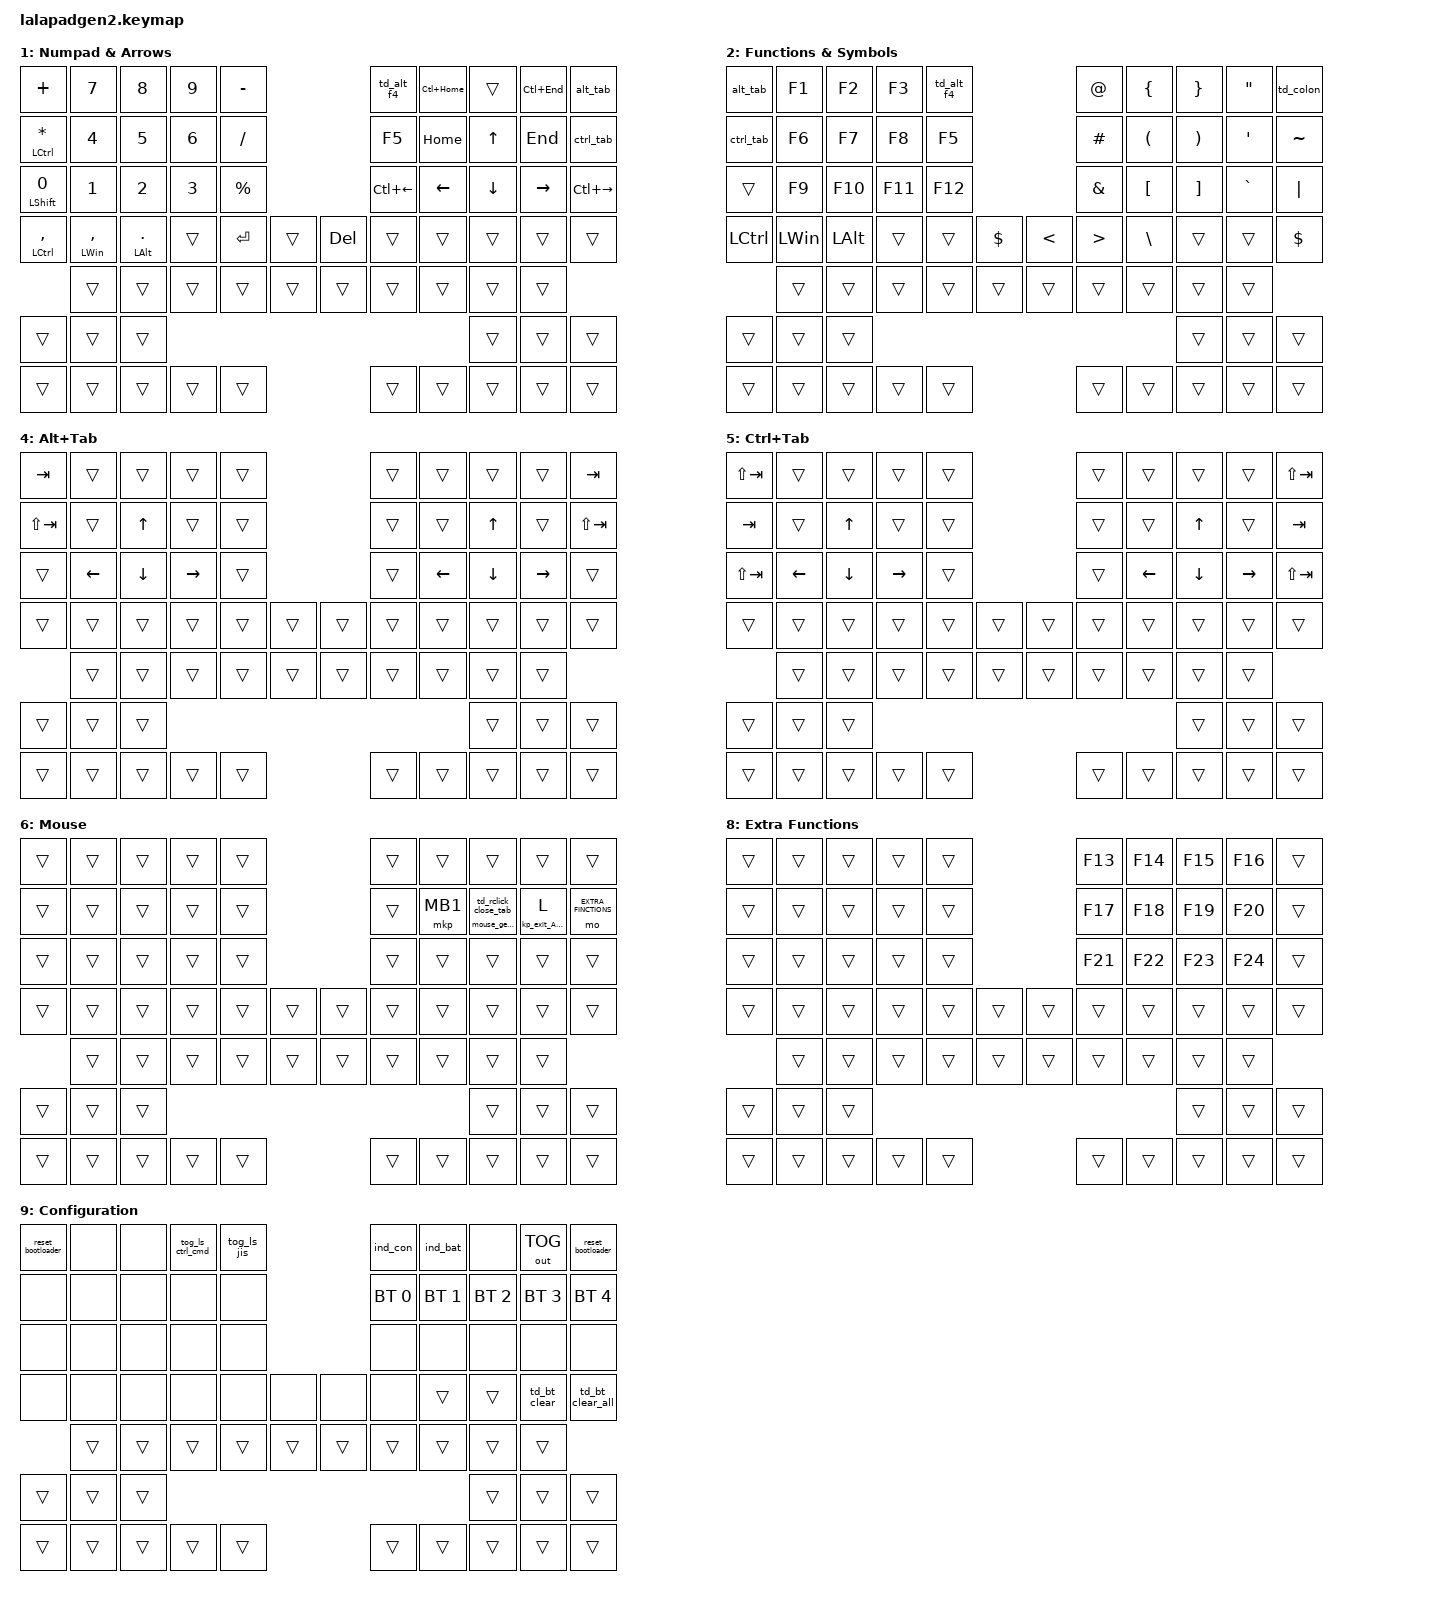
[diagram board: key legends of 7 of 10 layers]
#define ZMK_POINTING_DEFAULT_SCRL_VAL 1000

#include <input/processors.dtsi>
#include <dt-bindings/zmk/input_transform.h>
#include <zephyr/dt-bindings/input/input-event-codes.h>
#include <behaviors/rgbled_widget.dtsi>
#include <behaviors/quick_scroll.dtsi>
#include <input/processors/report_rate_limit.dtsi>


#include <behaviors.dtsi>
#include <dt-bindings/zmk/bt.h>
#include <dt-bindings/zmk/keys.h>
#include <dt-bindings/zmk/outputs.h>
#include <dt-bindings/zmk/pointing.h>

// #include <layout_shift.dtsi>
#include <layout_shift_kp_override.dtsi>

/ {
    behaviors {
        tog_ls_jis: tog_ls_jis {
            compatible = "zmk,behavior-layout-shift-toggle";
            #binding-cells = <0>;
            toggle-mode = "flip";
            label = "LAYOUT_SHIFT_TOGGLE_US_TO_JIS";
            display-name = "Toggle Layout Shift";
            layout-maps = <&layout_shift_map_us_to_jis>;
        };

        tog_ls_ctrl_cmd: tog_ls_ctrl_cmd {
            compatible = "zmk,behavior-layout-shift-toggle";
            #binding-cells = <0>;
            toggle-mode = "flip";
            label = "LAYOUT_SHIFT_TOGGLE_CTRL_CMD";
            display-name = "Toggle Layout Shift";
            layout-maps = <&layout_shift_map_swap_ctrl_cmd>;
        };
    };
};

&layout_shift_map_us_to_jis { priority = <0>; };
&layout_shift_map_swap_ctrl_cmd { priority = <1>; };

#include <mouse-gesture.dtsi>
#include <scroll-snap.dtsi>

#define DEFAULT 0
#define NUMPAD_AND_ARROWS 1
#define FUNCTIONS_AND_SYMBOLS 2
#define NAV 3
#define ALT_TAB 4
#define CTRL_TAB 5
#define MOUSE 6
#define MEDIA 7
#define EXTRA_FINCTIONS 8
#define CONFIGURATION 9

&qmsc {
    double-tap-ms = <350>;
};

&mt {
    tapping-term-ms = <200>;
    quick-tap-ms = <250>;
    flavor = "balanced";
};

&lt {
    tapping-term-ms = <200>;
    quick-tap-ms = <250>;
    flavor = "balanced";
};

&to { /delete-property/ locking; };

&tog { /delete-property/ locking; };

&sk { release-after-ms = <700>; };

&sl { release-after-ms = <1000>; };

&mouse_gesture_kp {
    tapping-term-ms = <200>;
    quick-tap-ms = <250>;
    flavor = "balanced";
};

&mouse_gesture_mkp {
    tapping-term-ms = <200>;
    quick-tap-ms = <250>;
    flavor = "balanced";
};

&zip_temp_layer {
    require-prior-idle-ms = <200>;
    excluded-positions = <
        16 17 18 19 // J K L ;
        20 29 30 // Z / Ctrl
        43 44 45 46 // Left directional switch
        47 48 49 50 // Right directional switch
    >;
};

&mkp_input_listener { input-processors = <&zip_temp_layer MOUSE 10000>; };

&zip_mouse_gesture {
    stroke-size = <150>;
    enable-eager-mode;
    suppress-movement;

    history_back {
        pattern = <GESTURE_RIGHT>;
        bindings = <&kp LA(LEFT)>;
    };

    history_forward {
        pattern = <GESTURE_LEFT>;
        bindings = <&kp LA(RIGHT)>;
    };

    close_tab {
        pattern = <GESTURE_DOWN GESTURE_RIGHT>;
        bindings = <&kp LC(W)>;
    };

    new_tab {
        pattern = <GESTURE_DOWN GESTURE_LEFT>;
        bindings = <&kp LC(T)>;
    };

    app_switcher {
        pattern = <GESTURE_DOWN GESTURE_UP>;
        bindings = <&kp LG(TAB)>;
    };

    virtual_desktop_prev {
        pattern = <GESTURE_LEFT GESTURE_DOWN>;
        bindings = <&kp LG(LC(LEFT))>;
    };

    virtual_desktop_next {
        pattern = <GESTURE_RIGHT GESTURE_DOWN>;
        bindings = <&kp LG(LC(RIGHT))>;
    };
};

&zip_scroll_snap {
    require-n-samples = <8>;
    immediate-snap-threshold = <750>;
    lock-duration-ms = <175>;
    lock-for-next-n-events = <8>;
    idle-reset-timeout-ms = <175>;
};

// &trackball_listener {
//     compatible = "zmk,input-listener";
//     input-processors = <
//         &zip_xy_transform (INPUT_TRANSFORM_XY_SWAP | INPUT_TRANSFORM_X_INVERT)
//         &zip_mouse_gesture
//         &zip_report_rate_limit 15
//         // &zip_cursor_snap
//     >;

//     auto-mouse-layer {
//         layers = <DEFAULT MOUSE>;
//         input-processors = <&zip_temp_layer MOUSE 10000>;
//         process-next;
//     };

//     scroller {
//         layers = <EXTRA_FINCTIONS MISC MEDIA>;
//         input-processors = <
//             &zip_xy_scaler 3 1
//             &zip_xy_transform (INPUT_TRANSFORM_XY_SWAP | INPUT_TRANSFORM_X_INVERT | INPUT_TRANSFORM_Y_INVERT)
//             &zip_xy_to_scroll_mapper
//             &zip_scroll_snap
//             &zip_report_rate_limit 15
//         >;

//         process-next;
//     };

//     disable-scroll-x {
//         layers = <EXTRA_FINCTIONS>;
//         input-processors = <&wheel_x_scaler 0 1>;

//         process-next;
//     };
// };

/ {
    input_processors {
        wheel_x_scaler: wheel_x_scaler {
            compatible = "zmk,input-processor-scaler";
            #input-processor-cells = <2>;
            type = <INPUT_EV_REL>;
            codes = <INPUT_REL_HWHEEL>;
            track-remainders;
        };
    };

    layer_listeners {
        compatible = "zmk,layer-listeners";

        // AML_indicator {
        //     layers = <MOUSE>;
        //     bindings = <&kp LS(LA(LC(LG(H)))) &kp LS(LA(LC(LG(H))))>;
        // };
        // AML {
        //     layers = <MOUSE>;
        //     bindings = <&to MOUSE &none>;
        // };
    };

    combos {
        compatible = "zmk,combos";

        eq {
            bindings = <&kp EQUAL>;
            key-positions = <0 1>;
            layers = <NUMPAD_AND_ARROWS>;
        };

        hat {
            bindings = <&kp CARET>;
            key-positions = <10 11>;
            layers = <NUMPAD_AND_ARROWS>;
        };

        middle_click {
            bindings = <&mkp MCLK>;
            key-positions = <18 19>;
            layers = <MOUSE>;
        };

        shift_middle_click {
            bindings = <&mkp_with_mod LEFT_SHIFT MCLK>;
            key-positions = <19 20>;
            layers = <MOUSE>;
        };

        Escape {
            bindings = <&kp ESCAPE>;
            key-positions = <0 1>;
            layers = <0>;
            require-prior-idle-ms = <300>;
        };

        caps_word {
            bindings = <&caps_word>;
            key-positions = <22 33>;
            layers = <0>;
            require-prior-idle-ms = <300>;
        };

        dot_slash_backslash {
            bindings = <&kp BACKSLASH>;
            key-positions = <33 32>;
            layers = <0>;
        };

        Ctrl_A {
            bindings = <&kp LC(A)>;
            key-positions = <10 11>;
            layers = <0>;
            require-prior-idle-ms = <300>;
        };

        Ctrl_Z {
            bindings = <&kp LC(Z)>;
            key-positions = <23 22>;
            layers = <0>;
            require-prior-idle-ms = <300>;
        };
    };

    macros {
        /omit-if-no-ref/

        exit_AML: exit_AML {
            compatible = "zmk,behavior-macro";
            wait-ms = <0>;
            tap-ms = <0>;
            #binding-cells = <0>;
            bindings = <&tog_off MOUSE>;
        };

        /omit-if-no-ref/

        kp_exit_AML: kp_exit_AML {
            compatible = "zmk,behavior-macro-one-param";
            wait-ms = <0>;
            tap-ms = <0>;
            #binding-cells = <1>;
            bindings = <&macro_param_1to1 &kp MACRO_PLACEHOLDER &exit_AML>;
        };

        /omit-if-no-ref/

        mod_exit_AML: mod_exit_AML {
            compatible = "zmk,behavior-macro-one-param";
            wait-ms = <0>;
            tap-ms = <0>;
            #binding-cells = <1>;
            bindings =
                <&macro_press>,
                <&macro_param_1to1 &kp MACRO_PLACEHOLDER>,
                <&macro_tap>,
                <&exit_AML>,
                <&macro_pause_for_release>,
                <&macro_release>,
                <&macro_param_1to1 &kp MACRO_PLACEHOLDER>;
        };

        /omit-if-no-ref/

        mkp_exit_AML: mkp_exit_AML {
            compatible = "zmk,behavior-macro-one-param";
            #binding-cells = <1>;
            bindings =
                <&macro_press>,
                <&macro_param_1to1 &mkp MACRO_PLACEHOLDER>,
                <&macro_pause_for_release>,
                <&macro_release>,
                <&macro_param_1to1 &mkp MACRO_PLACEHOLDER>,
                <&macro_tap>,
                <&sl MOUSE>;
        };

        /omit-if-no-ref/

        mo_exit_AML: mo_exit_AML {
            compatible = "zmk,behavior-macro-one-param";
            wait-ms = <0>;
            tap-ms = <0>;
            #binding-cells = <1>;
            bindings =
                <&macro_press>,
                <&macro_param_1to1 &mo MACRO_PLACEHOLDER>,
                <&macro_tap>,
                <&exit_AML>,
                <&macro_pause_for_release>,
                <&macro_release>,
                <&macro_param_1to1 &mo MACRO_PLACEHOLDER>,
                <&macro_tap>;
        };

        /omit-if-no-ref/

        ime_switch: ime_switch {
            compatible = "zmk,behavior-adaptive-key";
            #binding-cells = <0>;
            bindings = <&kp LANGUAGE_2>;

            ime_on {
                trigger-keys = <LANGUAGE_1 LANGUAGE_2>;
                bindings = <&kp LANGUAGE_1>;
                max-prior-idle-ms = <250>;
            };
        };

        /omit-if-no-ref/

        alt_tab: alt_tab {
            compatible = "zmk,behavior-smart-toggle";
            #binding-cells = <0>;
            bindings = <&mokp ALT_TAB LALT>, <&kp TAB>;
            ignored-key-positions = <
                10 19 // Shift+Tab
                12 21 22 23 17 26 27 28 // arrows
                13 16 52 53 54 55 56 57 // mouse clicks
            >;
        };

        /omit-if-no-ref/

        ctrl_tab: ctrl_tab {
            compatible = "zmk,behavior-smart-toggle";
            #binding-cells = <0>;
            bindings = <&mokp CTRL_TAB LCTRL>, <&kp TAB>;
            ignored-key-positions = <
                0 9 20 29 // Shift+Tab
                12 21 22 23 17 26 27 28 // arrows
                13 16 52 53 54 55 56 57 // mouse clicks
            >;
        };

        /omit-if-no-ref/

        mokp: mokp {
            compatible = "zmk,behavior-macro-two-param";
            wait-ms = <0>;
            tap-ms = <0>;
            #binding-cells = <2>;
            bindings =
                <&macro_press>,
                <&macro_param_1to1 &mo MACRO_PLACEHOLDER>,
                <&macro_param_2to1 &kp MACRO_PLACEHOLDER>,
                <&macro_pause_for_release>,
                <&macro_release>,
                <&macro_param_1to1 &mo MACRO_PLACEHOLDER>,
                <&macro_param_2to1 &kp MACRO_PLACEHOLDER>;
        };

        /omit-if-no-ref/

        kp_to: kp_to {
            compatible = "zmk,behavior-macro-two-param";
            wait-ms = <0>;
            tap-ms = <0>;
            #binding-cells = <2>;
            bindings = <&macro_param_1to1 &kp MACRO_PLACEHOLDER &macro_param_2to1 &to MACRO_PLACEHOLDER>;
        };

        /omit-if-no-ref/

        to_kp: to_kp {
            compatible = "zmk,behavior-macro-two-param";
            #binding-cells = <2>;
            bindings = <&macro_param_1to1 &to MACRO_PLACEHOLDER &macro_param_2to1 &kp MACRO_PLACEHOLDER>;
        };

        /omit-if-no-ref/

        zoom_in: zoom_in {
            compatible = "zmk,behavior-macro";
            #binding-cells = <0>;
            bindings = <&kt_on LCTRL &msc SCRL_UP &kt_off LCTRL>;
        };

        /omit-if-no-ref/

        zoom_out: zoom_out {
            compatible = "zmk,behavior-macro";
            #binding-cells = <0>;
            bindings = <&kt_on LCTRL &msc SCRL_DOWN &kt_off LCTRL>;
        };

    };

    behaviors {
        /omit-if-no-ref/

        tog_on: toggle_layer_on {
            compatible = "zmk,behavior-toggle-layer";
            #binding-cells = <1>;
            display-name = "Toggle Layer On";
            toggle-mode = "on";
        };

        /omit-if-no-ref/

        tog_off: toggle_layer_off {
            compatible = "zmk,behavior-toggle-layer";
            #binding-cells = <1>;
            display-name = "Toggle Layer Off";
            toggle-mode = "off";
        };

        /omit-if-no-ref/

        kt_on: key_toggle_on_only {
            compatible = "zmk,behavior-key-toggle";
            #binding-cells = <1>;
            display-name = "Key Toggle On";
            toggle-mode = "on";
        };

        /omit-if-no-ref/

        kt_off: key_toggle_off_only {
            compatible = "zmk,behavior-key-toggle";
            #binding-cells = <1>;
            display-name = "Key Toggle Off";
            toggle-mode = "off";
        };

        /omit-if-no-ref/

        td_colon: td_colon {
            compatible = "zmk,behavior-tap-dance";
            #binding-cells = <0>;
            bindings = <&kp COLON>, <&kp SEMICOLON>;

            tapping-term-ms = <250>;
        };

        /omit-if-no-ref/

        td_q_escape: td_q_escape {
            compatible = "zmk,behavior-tap-dance";
            #binding-cells = <0>;
            tapping-term-ms = <250>;
            bindings = <&kp Q>, <&kp ESCAPE>;
        };

        /omit-if-no-ref/

        td_ZenkakuHankaku: td_ZenkakuHankaku {
            compatible = "zmk,behavior-tap-dance";

            // compatible = "zmk,behavior-eager-tap-dance";

            #binding-cells = <0>;
            tapping-term-ms = <250>;
            bindings = <&kp LANGUAGE_2>, <&kp LANGUAGE_1>;
        };

        /omit-if-no-ref/

        td_ZenkakuHankaku_exit_AML: td_ZenkakuHankaku_exit_AML {
            wait-ms = <0>;
            tap-ms = <0>;
            compatible = "zmk,behavior-macro";
            #binding-cells = <0>;
            bindings = <&td_ZenkakuHankaku &exit_AML>;
        };

        /omit-if-no-ref/

        windows_sleep: windows_sleep {
            compatible = "zmk,behavior-macro";
            wait-ms = <200>;
            tap-ms = <100>;
            #binding-cells = <0>;
            bindings = <&kp LG(X) &kp U &kp S>;
        };

        /omit-if-no-ref/

        screensot_save: screensot_save {
            compatible = "zmk,behavior-macro";
            #binding-cells = <0>;
            bindings = <&kp LS(F11)>;
            label = "SCREENSOT_SAVE";
        };

        mkp_with_mod: mkp_with_mod {
            compatible = "zmk,behavior-macro-two-param";
            #binding-cells = <2>;
            bindings =
                <&macro_press>,
                <&macro_param_1to1 &kp MACRO_PLACEHOLDER &macro_param_2to1 &mkp MACRO_PLACEHOLDER>,
                <&macro_pause_for_release>,
                <&macro_release>,
                <&macro_param_2to1 &mkp MACRO_PLACEHOLDER &macro_param_1to1 &kp MACRO_PLACEHOLDER>;

            label = "MKP_WITH_MOD";
        };

        /omit-if-no-ref/

        screenshot_copy: screenshot_copy {
            compatible = "zmk,behavior-mod-morph";
            bindings = <&kp LA(PRINTSCREEN)>, <&kp LA(PRINTSCREEN)>;

            #binding-cells = <0>;
            mods = <(MOD_LSFT|MOD_LALT)>;
            keep-mods = <(MOD_LALT)>;
        };

        /omit-if-no-ref/

        mod_morph_exclamation: mod_morph_exclamation {
            compatible = "zmk,behavior-mod-morph";
            bindings = <&kp COMMA>, <&kp EXCL>;

            #binding-cells = <0>;
            mods = <(MOD_LSFT)>;
        };

        /omit-if-no-ref/

        mod_morph_question: mod_morph_question {
            compatible = "zmk,behavior-mod-morph";
            bindings = <&kp PERIOD>, <&kp QUESTION>;

            #binding-cells = <0>;
            mods = <(MOD_LSFT)>;
        };

        /omit-if-no-ref/

        mod_morph_slash: mod_morph_slash {
            compatible = "zmk,behavior-mod-morph";
            bindings = <&kp SLASH>, <&kp BACKSLASH>;

            #binding-cells = <0>;
            mods = <(MOD_LSFT)>;
        };

        /omit-if-no-ref/

        td_alt_f4: td_alt_f4 {
            compatible = "zmk,behavior-tap-dance";
            #binding-cells = <0>;
            bindings = <&kp F4>, <&kp LA(F4)>;

            tapping-term-ms = <250>;
        };

        /omit-if-no-ref/

        lt_exit_AML: lt_exit_AML {
            compatible = "zmk,behavior-hold-tap";
            bindings = <&mo_exit_AML>, <&kp_exit_AML>;

            #binding-cells = <2>;
            tapping-term-ms = <200>;
            quick-tap-ms = <200>;
            flavor = "balanced";
        };

        /omit-if-no-ref/

        lt_exit_AML_on_hold: lt_exit_AML_on_hold {
            compatible = "zmk,behavior-hold-tap";
            bindings = <&mo_exit_AML>, <&kp>;

            #binding-cells = <2>;
            tapping-term-ms = <200>;
            quick-tap-ms = <200>;
            flavor = "balanced";
        };

        /omit-if-no-ref/

        mt_exit_AML: mt_exit_AML {
            compatible = "zmk,behavior-hold-tap";
            bindings = <&mod_exit_AML>, <&kp_exit_AML>;

            #binding-cells = <2>;
            tapping-term-ms = <200>;
            flavor = "balanced";
            quick-tap-ms = <200>;
        };

        /omit-if-no-ref/

        mt_exit_AML_on_tap: mt_exit_AML_on_tap {
            compatible = "zmk,behavior-hold-tap";
            bindings = <&kp>, <&kp_exit_AML>;

            #binding-cells = <2>;
            tapping-term-ms = <200>;
            flavor = "balanced";
            quick-tap-ms = <200>;
        };

        /omit-if-no-ref/

        encoder_zoom: encoder_zoom {
            compatible = "zmk,behavior-sensor-rotate";
            #sensor-binding-cells = <0>;
            bindings = <&zoom_out>, <&zoom_in>;
        };

        /omit-if-no-ref/

        encoder_volume: encoder_volume {
            compatible = "zmk,behavior-sensor-rotate";
            #sensor-binding-cells = <0>;
            bindings = <&kp C_VOLUME_DOWN>, <&kp C_VOLUME_UP>;
        };

        // /omit-if-no-ref/

        lt_zoom_out: lt_zoom_out {
            compatible = "zmk,behavior-hold-tap";
            bindings = <&mo>, <&zoom_out>;

            #binding-cells = <2>;
            tapping-term-ms = <200>;
            quick-tap-ms = <200>;
            flavor = "balanced";
        };

        /omit-if-no-ref/

        td_bt_clear: td_bt_clear {
            compatible = "zmk,behavior-tap-dance";
            #binding-cells = <0>;
            bindings = <&none>, <&none>, <&bt BT_CLR>;

            tapping-term-ms = <250>;
        };

        /omit-if-no-ref/

        td_bt_clear_all: td_bt_clear_all {
            compatible = "zmk,behavior-tap-dance";
            #binding-cells = <0>;
            tapping-term-ms = <250>;
            bindings = <&none>, <&none>, <&bt BT_CLR_ALL>;
        };

        /omit-if-no-ref/

        td_copy_paste: td_copy_paste {
            compatible = "zmk,behavior-tap-dance";
            #binding-cells = <0>;
            bindings = <&kp_exit_AML LC(C)>, <&kp_exit_AML LC(V)>;

            tapping-term-ms = <250>;
        };

        /omit-if-no-ref/

        hold_bootloader: hold_bootloader {
            compatible = "zmk,behavior-hold-tap";
            #binding-cells = <2>;
            bindings = <&bootloader>, <&none>;
            tapping-term-ms = <250>;
            flavor = "tap-preferred";
        };

        /omit-if-no-ref/

        reset_bootloader: reset_bootloader {
            compatible = "zmk,behavior-tap-dance";
            #binding-cells = <0>;
            bindings = <&hold_bootloader 0 0>, <&sys_reset>;
            tapping-term-ms = <300>;
        };

        /omit-if-no-ref/

        td_rclick_close_tab: td_rclick_close_tab {
            compatible = "zmk,behavior-tap-dance";
            #binding-cells = <0>;
            bindings = <&mkp RCLK>, <&kp LC(W)>;

            tapping-term-ms = <250>;
        };

        /omit-if-no-ref/

        td_rclick_close_tab_mouse_gesture: td_rclick_close_tab_mouse_gesture {
            compatible = "zmk,behavior-hold-tap";
            #binding-cells = <2>;
            bindings = <&mouse_gesture>, <&td_rclick_close_tab>;

            tapping-term-ms = <150>;
            flavor = "balanced";
        };
    };

    keymap {
        compatible = "zmk,keymap";

        DEFAULT {
            display-name = "Default";
            bindings = <
&mt LWIN Q                        &mt LALT W        &kp E         &kp R         &kp T                                    &kp Y                    &kp U                    &kp I                   &kp O                &lt MEDIA P
&mt LCTRL A                       &kp S             &kp D         &kp F         &kp G                                    &kp H                    &kp J                    &mouse_gesture_kp 0 K   &kp L                &lt EXTRA_FINCTIONS MINUS
&mt_exit_AML_on_tap LEFT_SHIFT Z  &mt LEFT_SHIFT X  &kp C         &kp V                          &kp B                                                                        &kp N                    &kp M                    &mod_morph_exclamation  &mod_morph_question  &mt LEFT_SHIFT SLASH
&kp LCTRL                         &kp LEFT_WIN      &kp LEFT_ALT  &ime_switch   &lt FUNCTIONS_AND_SYMBOLS SPACE  &lt NAV TAB  &lt NAV BACKSPACE  &lt NUMPAD_AND_ARROWS ENTER  &lt NUMPAD_AND_ARROWS ENTER  &mo CONFIGURATION  &none  &lt EXTRA_FINCTIONS ESCAPE
                                  &none  &kp LG(LC(RIGHT))  &qmsc MOVE_Y(-120)  &kp LG(LC(LEFT))  &qmsc MOVE_Y(120)  &qmsc MOVE_Y(120)  &kp LA(LEFT)  &qmsc MOVE_Y(-120)  &kp LA(RIGHT)  &none
&mkp LCLK                         &mkp RCLK         &mkp MCLK                                                                                                                                                                   &mkp LCLK               &mkp RCLK            &mkp MCLK
&mkp MB4                          &mkp MB5          &kp LG(TAB)   &none                          &kp LCTRL                                                                    &kp LG(LC(LEFT))         &kp LG(LC(RIGHT))        &kp LG(TAB)             &none                &kp LCTRL
            >;
        };


        NUMPAD_AND_ARROWS {
            display-name = "Numpad & Arrows";
            bindings = <
&kp PLUS                   &kp N7              &kp N8               &kp N9  &kp MINUS                        &td_alt_f4    &kp LC(HOME)  &trans        &kp LC(END)  &alt_tab
&mt LEFT_CONTROL ASTERISK  &kp N4              &kp N5               &kp N6  &kp SLASH                        &kp F5        &kp HOME      &kp UP_ARROW  &kp END      &ctrl_tab
&mt LEFT_SHIFT N0          &kp N1              &kp N2               &kp N3  &kp PERCENT                      &kp LC(LEFT)  &kp LEFT      &kp DOWN      &kp RIGHT    &kp LC(RIGHT)
&mt LCTRL COMMA            &mt LEFT_WIN COMMA  &mt LEFT_ALT PERIOD  &trans  &kp ENTER    &trans  &kp DELETE  &trans        &trans        &trans        &trans       &trans
                           &trans              &trans               &trans  &trans       &trans  &trans      &trans        &trans        &trans        &trans
&trans                     &trans              &trans                                                                                    &trans        &trans       &trans
&trans                     &trans              &trans               &trans  &trans                           &trans        &trans        &trans        &trans       &trans
            >;
        };

        FUNCTIONS_AND_SYMBOLS {
            display-name = "Functions & Symbols";
            bindings = <
&alt_tab   &kp F1        &kp F2        &kp F3   &td_alt_f4                         &kp AT_SIGN       &kp LEFT_BRACE        &kp RIGHT_BRACE        &kp DOUBLE_QUOTES  &td_colon
&ctrl_tab  &kp F6        &kp F7        &kp F8   &kp F5                             &kp HASH          &kp LEFT_PARENTHESIS  &kp RIGHT_PARENTHESIS  &kp SINGLE_QUOTE   &kp TILDE
&trans        &kp F9        &kp F10       &kp F11  &kp F12                            &kp AMPERSAND     &kp LEFT_BRACKET      &kp RIGHT_BRACKET      &kp GRAVE          &kp PIPE
&kp LCTRL  &kp LEFT_WIN  &kp LEFT_ALT  &trans   &trans      &kp DOLLAR  &kp LESS_THAN  &kp GREATER_THAN  &kp BSLH  &trans  &trans  &kp DOLLAR
              &trans        &trans        &trans   &trans      &trans  &trans         &trans            &trans                &trans                 &trans
&trans        &trans        &trans                                                                                            &trans                 &trans             &trans
&trans        &trans        &trans        &trans   &trans                             &trans            &trans                &trans                 &trans             &trans
            >;
        };

        NAV {
            display-name = "Navigations";
            bindings = <
&alt_tab              &kp LC(LG(LEFT))        &kp LG(TAB)       &kp LG(LC(RIGHT))        &trans                                &trans      &kp LC(W)                 &kp LS(LC(T))             &kp LC(T)          &alt_tab
&ctrl_tab             &kp LG(LS(LEFT_ARROW))  &kp LG(UP_ARROW)  &kp LG(LS(RIGHT_ARROW))  &trans                                &trans      &kp_exit_AML LC(PAGE_UP)  &kp_exit_AML LA(UP_ARROW)  &kp LC(PAGE_DOWN)  &ctrl_tab
&kp LA(LC(LG(DOWN)))  &kp LG(LEFT_ARROW)      &kp LG(DOWN)      &kp LG(RIGHT_ARROW)      &screenshot_copy                      &kp C_MUTE  &kp LA(LEFT)              &kp LA(DOWN)               &kp LA(RIGHT)      &trans
&trans                &trans                  &trans            &trans                   &trans  &screensot_save  &kp C_VOLUME_UP  &kp DELETE  &kp_exit_AML C_VOLUME_DOWN  &trans  &trans  &trans
                      &trans                  &trans            &trans                   &trans            &trans  &trans      &trans      &trans                    &trans                 &trans
&trans                &trans                  &trans                                                                                                                 &trans                 &trans             &trans
&trans                &trans                  &trans            &trans                   &trans                                &trans      &trans                    &trans                 &trans             &trans
            >;
        };

        ALT_TAB {
            display-name = "Alt+Tab";
            bindings = <
&kp TAB      &trans    &trans    &trans     &trans                  &trans  &trans    &trans    &trans     &kp TAB
&kp LS(TAB)  &trans    &kp UP    &trans     &trans                  &trans  &trans    &kp UP    &trans     &kp LS(TAB)
&trans       &kp LEFT  &kp DOWN  &kp RIGHT  &trans                  &trans  &kp LEFT  &kp DOWN  &kp RIGHT  &trans
&trans       &trans    &trans    &trans     &trans  &trans  &trans  &trans  &trans    &trans    &trans     &trans
             &trans    &trans    &trans     &trans  &trans  &trans  &trans  &trans    &trans    &trans
&trans       &trans    &trans                                                         &trans    &trans     &trans
&trans       &trans    &trans    &trans     &trans                  &trans  &trans    &trans    &trans     &trans
            >;
        };

        CTRL_TAB {
            display-name = "Ctrl+Tab";
            bindings = <
&kp LS(TAB)  &trans    &trans    &trans     &trans                  &trans  &trans    &trans    &trans     &kp LS(TAB)
&kp TAB      &trans    &kp UP    &trans     &trans                  &trans  &trans    &kp UP    &trans     &kp TAB
&kp LS(TAB)  &kp LEFT  &kp DOWN  &kp RIGHT  &trans                  &trans  &kp LEFT  &kp DOWN  &kp RIGHT  &kp LS(TAB)
&trans       &trans    &trans    &trans     &trans  &trans  &trans  &trans  &trans    &trans    &trans     &trans
             &trans    &trans    &trans     &trans  &trans  &trans  &trans  &trans    &trans    &trans
&trans       &trans    &trans                                                         &trans    &trans     &trans
&trans       &trans    &trans    &trans     &trans                  &trans  &trans    &trans    &trans     &trans
            >;
        };

        MOUSE {
            display-name = "Mouse";
            bindings = <
&trans  &trans  &trans  &trans   &trans                  &trans  &trans    &trans                                  &trans  &trans
&trans  &trans  &trans  &trans  &trans                  &trans  &mkp MB1  &td_rclick_close_tab_mouse_gesture 0 0  &kp_exit_AML L  &mo EXTRA_FINCTIONS
&trans  &trans  &trans  &trans   &trans                  &trans  &trans    &trans                                  &trans  &trans
&trans  &trans  &trans  &trans   &trans  &trans  &trans  &trans  &trans    &trans                                  &trans  &trans
        &trans  &trans  &trans  &trans   &trans  &trans  &trans  &trans  &trans  &trans
&trans  &trans  &trans                                                     &trans                                  &trans  &trans
&trans  &trans  &trans  &trans   &trans                  &trans  &trans    &trans                                  &trans  &trans
            >;
        };

        MEDIA {
            display-name = "Media";
            bindings = <
&trans  &trans  &trans  &trans  &trans                  &kp C_PREV         &kp C_PLAY_PAUSE   &kp C_NEXT       &trans  &trans
&trans  &trans  &trans  &trans  &trans                  &kp C_VOLUME_DOWN  &kp C_MUTE         &kp C_VOLUME_UP  &trans  &trans
&trans  &trans  &trans  &trans  &trans                  &trans             &kp LS(LA(LC(M)))  &trans           &trans  &trans
&trans  &trans  &trans  &trans  &trans  &trans  &trans  &trans             &trans             &trans           &trans  &trans
        &trans  &trans  &trans  &trans  &trans  &trans  &trans             &trans             &trans           &trans
&trans  &trans  &trans                                                                        &trans           &trans  &trans
&trans  &trans  &trans  &trans  &trans                  &trans             &trans             &trans           &trans  &trans
            >;
        };

        EXTRA_FINCTIONS {
            display-name = "Extra Functions";
            bindings = <
&trans  &trans  &trans  &trans                         &trans                  &kp F13  &kp F14  &kp F15  &kp F16  &trans
&trans  &trans  &trans  &trans                         &trans                  &kp F17  &kp F18  &kp F19  &kp F20  &trans
&trans  &trans  &trans  &trans                         &trans                  &kp F21  &kp F22  &kp F23  &kp F24  &trans
&trans  &trans  &trans  &trans  &trans  &trans  &trans  &trans  &trans  &trans  &trans  &trans
        &trans  &trans  &trans                         &trans  &trans  &trans  &trans   &trans   &trans   &trans
&trans  &trans  &trans                                                                           &trans   &trans   &trans
&trans  &trans  &trans  &trans                         &trans                  &trans   &trans   &trans   &trans   &trans
            >;
        };

        CONFIGURATION {
            display-name = "Configuration";
            bindings = <
&reset_bootloader  &none  &none  &tog_ls_ctrl_cmd  &tog_ls_jis  &ind_con  &ind_bat  &none  &out OUT_TOG  &reset_bootloader
&none                  &none  &none  &none             &none        &bt BT_SEL 0  &bt BT_SEL 1  &bt BT_SEL 2  &bt BT_SEL 3  &bt BT_SEL 4
&none                  &none  &none  &none             &none        &none  &none  &none  &none  &none
&none                  &none   &none   &none   &none        &none   &none   &none         &trans        &trans        &td_bt_clear  &td_bt_clear_all
                       &trans  &trans  &trans  &trans       &trans  &trans  &trans        &trans        &trans        &trans
&trans                 &trans  &trans                                                                   &trans        &trans        &trans
&trans                 &trans  &trans  &trans  &trans                       &trans        &trans        &trans        &trans        &trans
            >;
        };
    };
};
